# M344 register map
File version: 2.0.2.6
Registers are 32-bit, read-write, reset 0x0 unless marked. A register's access mark holds for its fields unless they carry their own. Offsets are from the block's base; [hi:lo] are bit positions; {n}, {i} and the like mark numbered series; 'fields as' and 'values as' point back to an identical list.

## PSCA — Programmable Servo Controller
Base 0x40118000
Same registers: PSCB 0x40218000, PSCC 0x40318000, PSCD 0x40418000
0x00 UA0 — Accumulator
0x04 UM0 — Multiplier Register
0x08 UM1 — Shift Count Register
0x0C UL0 — Upper Limit Value Register
0x10 UL1 — Lower Limit Value Register
0x14 UR0 — Add Sub Value Register 0
0x18 UR1 — Add Sub Value Register 1
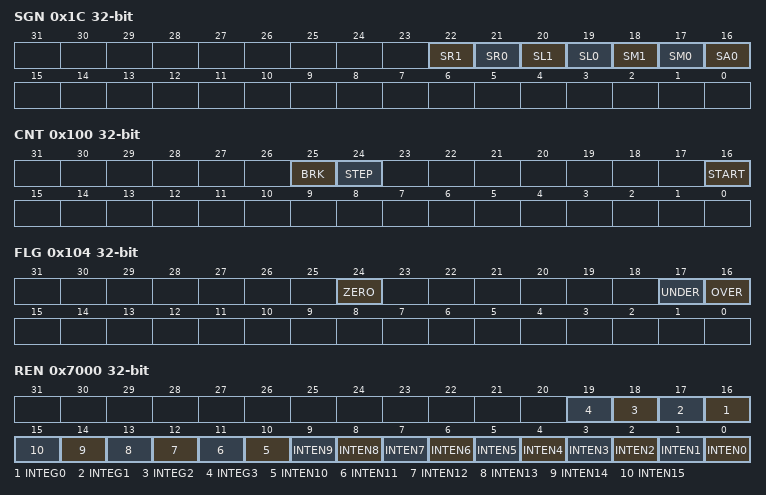
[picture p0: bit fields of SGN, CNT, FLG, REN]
0x1C SGN — Arithmetic Parameter with Signed Register
  [22] SR1, [21] SR0, [20] SL1, [19] SL0, [18] SM1, [17] SM0, [16] SA0
{0x20+4i} AP{i} (i=0..3) — Address Pointer {i}
0x30 BR0 — Break Pointer
0x34 PG0 — Program Counter
0x38 VG0 — Repeat Processing Vector Pointer
0x100 CNT — Control Register
  [25] BRK, [24] STEP, [16] START
0x104 FLG — Flag Register
  [24] ZERO, [17] UNDER, [16] OVER
0x7000 REN — Run Trigger Enable Register
  [n+16] INTEG{n} (n=0..3), [n] INTEN{n} (n=0..15)
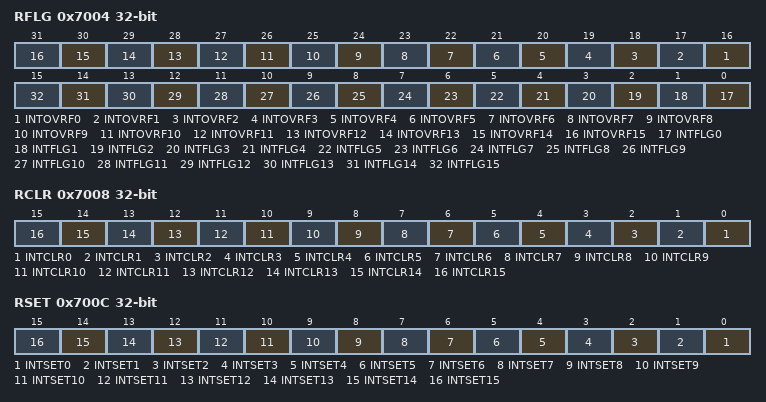
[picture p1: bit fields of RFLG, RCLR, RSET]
0x7004 RFLG ro — Run Trigger Flag Register
  [n+16] INTOVRF{n} (n=0..15), [n] INTFLG{n} (n=0..15)
0x7008 RCLR wo — Run Trigger Clear Register
  [n] INTCLR{n} (n=0..15)
0x700C RSET wo — Run Trigger Clear Register
  [n] INTSET{n} (n=0..15)
0x7100 PTOUT — Port Output Enable Register for PSC
  [7:0] PSCPTO
0x7104 PTCR — Port Control Register for PSC
  [7:0] PSCPTC
0x7108 PTIN ro — Port Input Enable Register for PSC
  [7:0] PSCPTI

## UART
Base 0x40448000
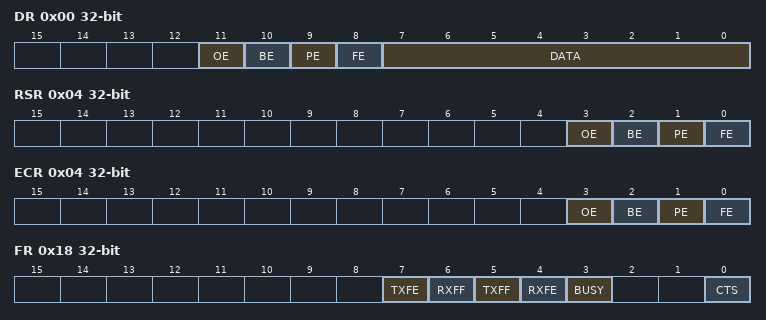
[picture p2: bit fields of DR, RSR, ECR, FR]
0x00 DR — Data Register
  [11] OE ro, [10] BE ro, [9] PE ro, [8] FE ro, [7:0] DATA
0x04 RSR ro — Receive Status Register
  [3] OE, [2] BE, [1] PE, [0] FE
0x04 ECR wo — Error Clear Register
  [3] OE, [2] BE, [1] PE, [0] FE
0x18 FR ro — Flag Register
  [7] TXFE, [6] RXFF, [5] TXFF, [4] RXFE, [3] BUSY, [0] CTS
0x24 IBRD — Integer Baud Rate Register
  [15:0] BAUDDIVINT
0x28 FBRD — Fractional Baud Rate Register
  [5:0] BAUDDIVFRAC
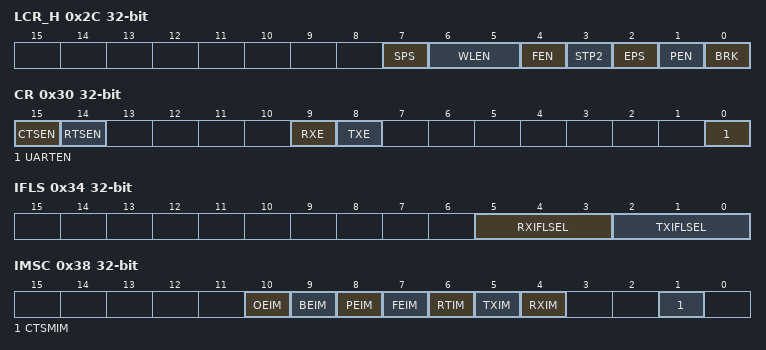
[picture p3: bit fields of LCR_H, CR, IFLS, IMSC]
0x2C LCR_H — Line Control Register
  [7] SPS, [6:5] WLEN, [4] FEN, [3] STP2, [2] EPS, [1] PEN, [0] BRK
0x30 CR — Control Register
  [15] CTSEN, [14] RTSEN, [9] RXE, [8] TXE, [0] UARTEN
0x34 IFLS — Interrupt FIFO Level Select Register
  [5:3] RXIFLSEL, [2:0] TXIFLSEL
0x38 IMSC — Interrupt Mask Set_Clear Register
  [10] OEIM, [9] BEIM, [8] PEIM, [7] FEIM, [6] RTIM, [5] TXIM, [4] RXIM, [1] CTSMIM
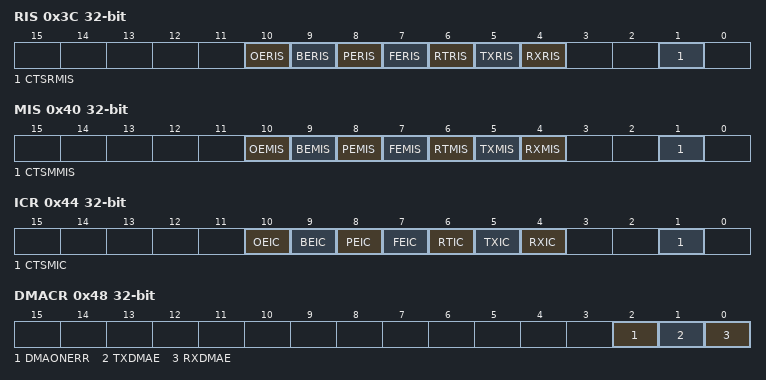
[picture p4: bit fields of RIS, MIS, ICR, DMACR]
0x3C RIS ro (reset mask 0xFFFFFFF0) — Raw Interrupt Status Register
  [10] OERIS, [9] BERIS, [8] PERIS, [7] FERIS, [6] RTRIS, [5] TXRIS, [4] RXRIS, [1] CTSRMIS
0x40 MIS ro (reset mask 0xFFFFFFF0) — Masked Interrupt Status Register
  [10] OEMIS, [9] BEMIS, [8] PEMIS, [7] FEMIS, [6] RTMIS, [5] TXMIS, [4] RXMIS, [1] CTSMMIS
0x44 ICR wo — Interrupt Clear Register
  [10] OEIC, [9] BEIC, [8] PEIC, [7] FEIC, [6] RTIC, [5] TXIC, [4] RXIC, [1] CTSMIC
0x48 DMACR — DMA Control Register
  [2] DMAONERR, [1] TXDMAE, [0] RXDMAE

## ADA — 12bit A_D Converter
Base 0x40050000
Same registers: ADB 0x40051000, ADC 0x40052000
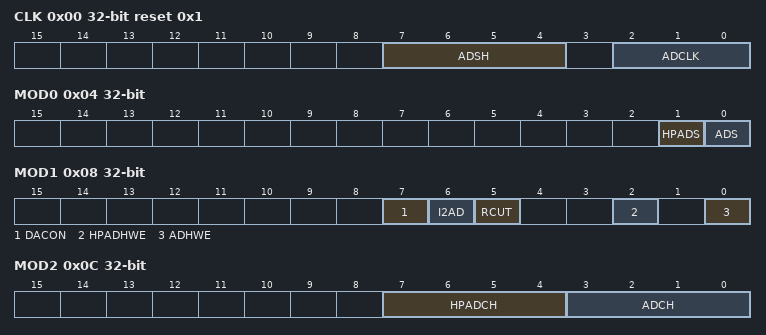
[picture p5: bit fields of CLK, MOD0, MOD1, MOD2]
0x00 CLK reset 0x1 — Conversion Clock Setting Register
  [7:4] ADSH, [2:0] ADCLK
0x04 MOD0 wo — Mode Control Register0
  [1] HPADS, [0] ADS
0x08 MOD1 — Mode Control Register1
  [7] DACON, [6] I2AD, [5] RCUT, [2] HPADHWE, [0] ADHWE
0x0C MOD2 — Mode Control Register2
  [7:4] HPADCH, [3:0] ADCH
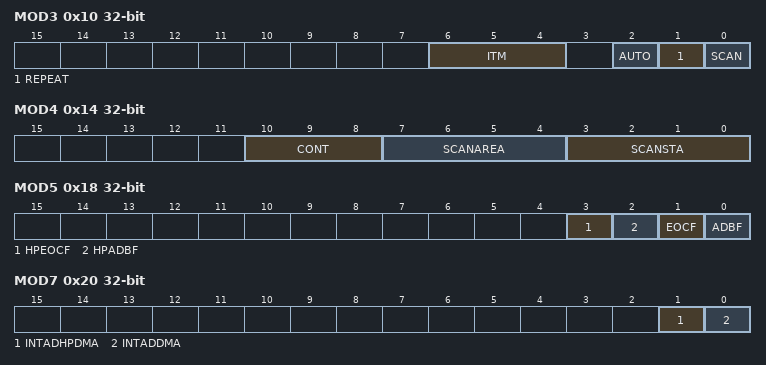
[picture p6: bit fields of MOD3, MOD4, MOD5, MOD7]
0x10 MOD3 — Mode Control Register3
  [6:4] ITM, [2] AUTO, [1] REPEAT, [0] SCAN
0x14 MOD4 — Mode Control Register4
  [10:8] CONT, [7:4] SCANAREA, [3:0] SCANSTA
0x18 MOD5 ro — Mode Control Register5
  [3] HPEOCF, [2] HPADBF, [1] EOCF, [0] ADBF
0x1C MOD6 — Mode Control Register6
  [1:0] ADRST wo
0x20 MOD7 — Mode Control Register7
  [1] INTADHPDMA, [0] INTADDMA
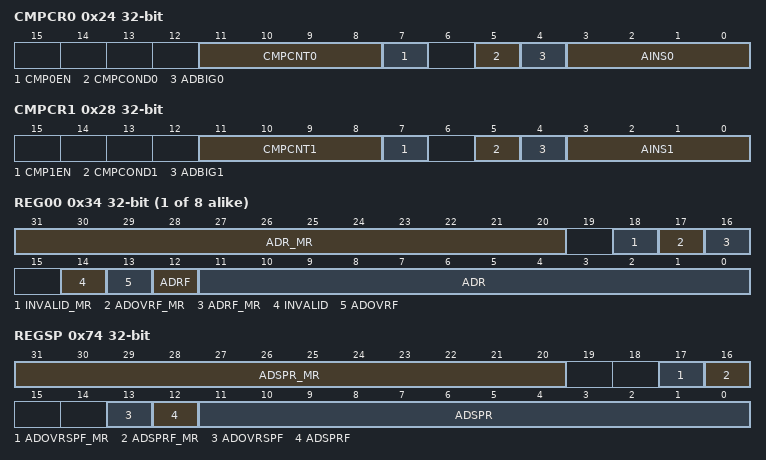
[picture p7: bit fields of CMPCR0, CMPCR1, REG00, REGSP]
0x24 CMPCR0 — Monitoring Interrupt Control Register0
  [11:8] CMPCNT0, [7] CMP0EN, [5] CMPCOND0, [4] ADBIG0, [3:0] AINS0
0x28 CMPCR1 — Monitoring Interrupt Control Register1
  [11:8] CMPCNT1, [7] CMP1EN, [5] CMPCOND1, [4] ADBIG1, [3:0] AINS1
0x2C CMP0 — Conversion Result Compare Register0
  [11:0] AD0CMP
0x30 CMP1 — Conversion Result Compare Register1
  [11:0] AD1CMP
{0x34+4i} REG{i:02} ro (i=0..7) — Conversion Result Store Register{i}
  [31:20] ADR_MR, [18] INVALID_MR, [17] ADOVRF_MR, [16] ADRF_MR, [14] INVALID, [13] ADOVRF, [12] ADRF, [11:0] ADR
0x74 REGSP ro — Highest Priority Conversion Result Store Register
  [31:20] ADSPR_MR, [17] ADOVRSPF_MR, [16] ADSPRF_MR, [13] ADOVRSPF, [12] ADSPRF, [11:0] ADSPR
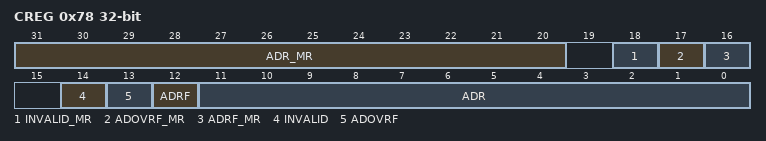
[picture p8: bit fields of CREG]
0x78 CREG ro — Conversion Result Store Common Register
  fields as REG00

## ADB_PSC — 12-bit AD converter(UnitB) Mirror
Base 0x40179000
Registers as ADA, without CLK, MOD{n} (n=0..7), CMPCR0, CMPCR1, CMP0, CMP1.

## ADC_PSC — 12-bit AD converter(UnitC) Mirror
Base 0x4027A000
Registers as ADA, without CLK, MOD{n} (n=0..7), CMPCR0, CMPCR1, CMP0, CMP1.

## ADA_PSC — 12-bit AD converter(UnitA) Mirror
Base 0x40374000
Registers as ADA, without CLK, MOD{n} (n=0..7), CMPCR0, CMPCR1, CMP0, CMP1.
